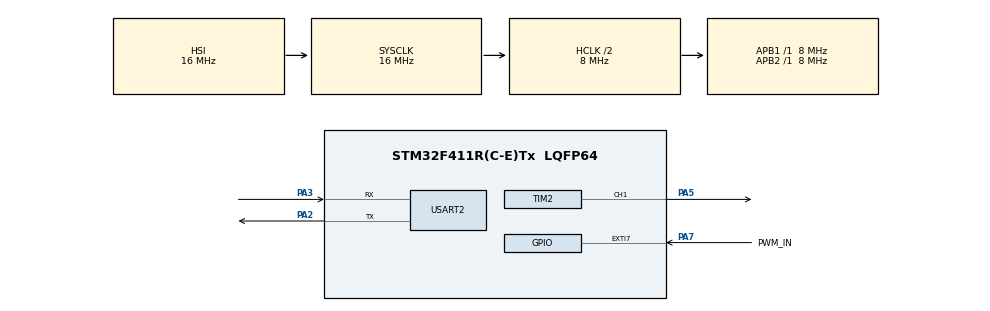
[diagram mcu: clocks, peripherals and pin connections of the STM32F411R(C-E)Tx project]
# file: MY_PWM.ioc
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Mcu.Family=STM32F4
Mcu.Name=STM32F411R(C-E)Tx
Mcu.Package=LQFP64
NVIC.EXTI9_5_IRQn=true\:0\:0\:false\:false\:true\:true\:true\:true
NVIC.PriorityGroup=NVIC_PRIORITYGROUP_4
PA13.Mode=Serial_Wire
PA13.Signal=SYS_JTMS-SWDIO
PA14.Mode=Serial_Wire
PA14.Signal=SYS_JTCK-SWCLK
PA2.Mode=Asynchronous
PA2.Signal=USART2_TX
PA3.Mode=Asynchronous
PA3.Signal=USART2_RX
PA5.Signal=S_TIM2_CH1_ETR
PA7.GPIO_Label=PWM_IN
PA7.GPIO_ModeDefaultEXTI=GPIO_MODE_IT_RISING
PA7.Signal=GPXTI7
ProjectManager.HeapSize=0x200
ProjectManager.StackSize=0x400
ProjectManager.TargetToolchain=STM32CubeIDE
RCC.AHBCLKDivider=RCC_SYSCLK_DIV2
RCC.AHBFreq_Value=8000000
RCC.APB1Freq_Value=8000000
RCC.APB1TimFreq_Value=8000000
RCC.APB2Freq_Value=8000000
RCC.APB2TimFreq_Value=8000000
RCC.CortexFreq_Value=8000000
RCC.HCLKFreq_Value=8000000
RCC.HSE_VALUE=25000000
RCC.HSI_VALUE=16000000
RCC.IWDGEnable-ClockTree=true
RCC.LSE_VALUE=32768
RCC.SYSCLKFreq_VALUE=16000000
RCC.VCOOutputFreq_Value=192000000
SH.S_TIM2_CH1_ETR.0=TIM2_CH1,PWM Generation1 CH1
TIM2.Channel-PWM\ Generation1\ CH1=TIM_CHANNEL_1
TIM2.Period=31249
TIM2.Prescaler=255
TIM2.Pulse-PWM\ Generation1\ CH1=15625
USART2.Parity=PARITY_NONE
USART2.VirtualMode=VM_ASYNC
USART2.WordLength=WORDLENGTH_8B
VP_TIM2_VS_ClockSourceINT.Mode=Internal
board=custom

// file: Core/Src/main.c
/* USER CODE BEGIN Header */
/**
 ******************************************************************************
 * @file           : main.c
 * @brief          : Main program body
 ******************************************************************************
 * @attention
 *
 * Copyright (c) 2025 STMicroelectronics.
 * All rights reserved.
 *
 * This software is licensed under terms that can be found in the LICENSE file
 * in the root directory of this software component.
 * If no LICENSE file comes with this software, it is provided AS-IS.
 *
 ******************************************************************************
 */
/* USER CODE END Header */
#include "main.h"

TIM_HandleTypeDef htim2;

UART_HandleTypeDef huart2;

/* USER CODE BEGIN PV */
uint8_t flag = 0;
/* USER CODE END PV */

void SystemClock_Config(void);
static void MX_GPIO_Init(void);
static void MX_TIM2_Init(void);
static void MX_USART2_UART_Init(void);

int main(void)
{

  /* MCU Configuration--------------------------------------------------------*/

  /* Reset of all peripherals, Initializes the Flash interface and the Systick. */
  HAL_Init();

  /* Configure the system clock */
  SystemClock_Config();

  /* Initialize all configured peripherals */
  MX_GPIO_Init();
  MX_TIM2_Init();
  MX_USART2_UART_Init();
  /* USER CODE BEGIN 2 */
  HAL_TIM_PWM_Start(&htim2, TIM_CHANNEL_1);

  char saluto[] = "Ciao Benny! ";
  uint8_t dim = sizeof(saluto) / sizeof(char);
  /* USER CODE END 2 */

  /* Infinite loop */
  /* USER CODE BEGIN WHILE */
  while (1)
  {
    if (flag == 1)
    {
      if (HAL_UART_Transmit(&huart2, saluto, dim , 500) != HAL_OK)
      {
        Error_Handler();
      }
      flag = 0;
    }
    /* USER CODE END WHILE */

  }
}

void SystemClock_Config(void)
{
  RCC_OscInitTypeDef RCC_OscInitStruct = {0};
  RCC_ClkInitTypeDef RCC_ClkInitStruct = {0};

  /** Configure the main internal regulator output voltage
   */
  __HAL_RCC_PWR_CLK_ENABLE();
  __HAL_PWR_VOLTAGESCALING_CONFIG(PWR_REGULATOR_VOLTAGE_SCALE1);

  /** Initializes the RCC Oscillators according to the specified parameters
   * in the RCC_OscInitTypeDef structure.
   */
  RCC_OscInitStruct.OscillatorType = RCC_OSCILLATORTYPE_HSI;
  RCC_OscInitStruct.HSIState = RCC_HSI_ON;
  RCC_OscInitStruct.HSICalibrationValue = RCC_HSICALIBRATION_DEFAULT;
  RCC_OscInitStruct.PLL.PLLState = RCC_PLL_NONE;
  if (HAL_RCC_OscConfig(&RCC_OscInitStruct) != HAL_OK)
  {
    Error_Handler();
  }

  /** Initializes the CPU, AHB and APB buses clocks
   */
  RCC_ClkInitStruct.ClockType = RCC_CLOCKTYPE_HCLK | RCC_CLOCKTYPE_SYSCLK | RCC_CLOCKTYPE_PCLK1 | RCC_CLOCKTYPE_PCLK2;
  RCC_ClkInitStruct.SYSCLKSource = RCC_SYSCLKSOURCE_HSI;
  RCC_ClkInitStruct.AHBCLKDivider = RCC_SYSCLK_DIV2;
  RCC_ClkInitStruct.APB1CLKDivider = RCC_HCLK_DIV1;
  RCC_ClkInitStruct.APB2CLKDivider = RCC_HCLK_DIV1;

  if (HAL_RCC_ClockConfig(&RCC_ClkInitStruct, FLASH_LATENCY_0) != HAL_OK)
  {
    Error_Handler();
  }
}

static void MX_TIM2_Init(void)
{

  TIM_ClockConfigTypeDef sClockSourceConfig = {0};
  TIM_MasterConfigTypeDef sMasterConfig = {0};
  TIM_OC_InitTypeDef sConfigOC = {0};

  htim2.Instance = TIM2;
  htim2.Init.Prescaler = 255;
  htim2.Init.CounterMode = TIM_COUNTERMODE_UP;
  htim2.Init.Period = 31249;
  htim2.Init.ClockDivision = TIM_CLOCKDIVISION_DIV1;
  htim2.Init.AutoReloadPreload = TIM_AUTORELOAD_PRELOAD_DISABLE;
  if (HAL_TIM_Base_Init(&htim2) != HAL_OK)
  {
    Error_Handler();
  }
  sClockSourceConfig.ClockSource = TIM_CLOCKSOURCE_INTERNAL;
  if (HAL_TIM_ConfigClockSource(&htim2, &sClockSourceConfig) != HAL_OK)
  {
    Error_Handler();
  }
  if (HAL_TIM_PWM_Init(&htim2) != HAL_OK)
  {
    Error_Handler();
  }
  sMasterConfig.MasterOutputTrigger = TIM_TRGO_RESET;
  sMasterConfig.MasterSlaveMode = TIM_MASTERSLAVEMODE_DISABLE;
  if (HAL_TIMEx_MasterConfigSynchronization(&htim2, &sMasterConfig) != HAL_OK)
  {
    Error_Handler();
  }
  sConfigOC.OCMode = TIM_OCMODE_PWM1;
  sConfigOC.Pulse = 15625;
  sConfigOC.OCPolarity = TIM_OCPOLARITY_HIGH;
  sConfigOC.OCFastMode = TIM_OCFAST_DISABLE;
  if (HAL_TIM_PWM_ConfigChannel(&htim2, &sConfigOC, TIM_CHANNEL_1) != HAL_OK)
  {
    Error_Handler();
  }
  HAL_TIM_MspPostInit(&htim2);
}

static void MX_USART2_UART_Init(void)
{

  huart2.Instance = USART2;
  huart2.Init.BaudRate = 115200;
  huart2.Init.WordLength = UART_WORDLENGTH_8B;
  huart2.Init.StopBits = UART_STOPBITS_1;
  huart2.Init.Parity = UART_PARITY_NONE;
  huart2.Init.Mode = UART_MODE_TX_RX;
  huart2.Init.HwFlowCtl = UART_HWCONTROL_NONE;
  huart2.Init.OverSampling = UART_OVERSAMPLING_16;
  if (HAL_UART_Init(&huart2) != HAL_OK)
  {
    Error_Handler();
  }
}

static void MX_GPIO_Init(void)
{
  GPIO_InitTypeDef GPIO_InitStruct = {0};

  /* GPIO Ports Clock Enable */
  __HAL_RCC_GPIOA_CLK_ENABLE();

  /*Configure GPIO pin : PWM_IN_Pin */
  GPIO_InitStruct.Pin = PWM_IN_Pin;
  GPIO_InitStruct.Mode = GPIO_MODE_IT_RISING;
  GPIO_InitStruct.Pull = GPIO_NOPULL;
  HAL_GPIO_Init(PWM_IN_GPIO_Port, &GPIO_InitStruct);

  /* EXTI interrupt init*/
  HAL_NVIC_SetPriority(EXTI9_5_IRQn, 0, 0);
  HAL_NVIC_EnableIRQ(EXTI9_5_IRQn);

}

/* USER CODE BEGIN 4 */
void HAL_GPIO_EXTI_Callback(uint16_t GPIO_Pin)
{
  flag = 1;
}

/* USER CODE END 4 */

void Error_Handler(void)
{
  __disable_irq();
  while (1)
  {
  }
}
